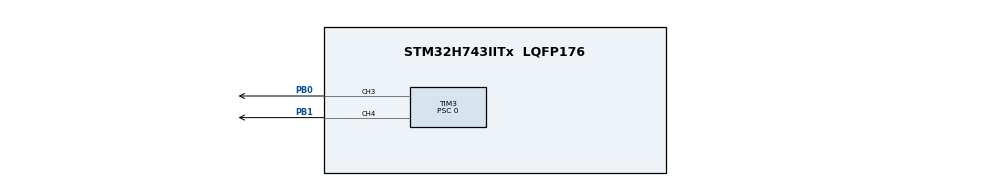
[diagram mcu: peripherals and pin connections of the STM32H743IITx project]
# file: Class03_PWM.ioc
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Mcu.Family=STM32H7
Mcu.Name=STM32H743IITx
Mcu.Package=LQFP176
NVIC.PriorityGroup=NVIC_PRIORITYGROUP_4
PB0.GPIO_Speed=GPIO_SPEED_FREQ_VERY_HIGH
PB0.Signal=S_TIM3_CH3
PB1.GPIO_PuPd=GPIO_NOPULL
PB1.GPIO_Speed=GPIO_SPEED_FREQ_VERY_HIGH
PB1.Signal=S_TIM3_CH4
PH0-OSC_IN.Mode=HSE-External-Oscillator
PH0-OSC_IN.Signal=RCC_OSC_IN
PH1-OSC_OUT.Mode=HSE-External-Oscillator
PH1-OSC_OUT.Signal=RCC_OSC_OUT
ProjectManager.HeapSize=0x200
ProjectManager.StackSize=0x400
ProjectManager.TargetToolchain=MDK-ARM V5
RCC.ADCFreq_Value=50390625
RCC.APB1Freq_Value=100000000
RCC.APB2Freq_Value=100000000
RCC.APB3Freq_Value=100000000
RCC.APB4Freq_Value=100000000
RCC.CortexFreq_Value=400000000
RCC.D1PPRE=RCC_APB3_DIV2
RCC.D2PPRE1=RCC_APB1_DIV2
RCC.D2PPRE2=RCC_APB2_DIV2
RCC.D3PPRE=RCC_APB4_DIV2
RCC.DIVM1=2
RCC.DIVN1=64
RCC.HCLKFreq_Value=200000000
RCC.HPRE=RCC_HCLK_DIV2
RCC.PLLSourceVirtual=RCC_PLLSOURCE_HSE
RCC.SYSCLKFreq_VALUE=400000000
RCC.SYSCLKSource=RCC_SYSCLKSOURCE_PLLCLK
RCC.USBFreq_Value=400000000
SH.S_TIM3_CH3.0=TIM3_CH3,PWM Generation3 CH3
SH.S_TIM3_CH4.0=TIM3_CH4,PWM Generation4 CH4
TIM3.AutoReloadPreload=TIM_AUTORELOAD_PRELOAD_ENABLE
TIM3.Channel-PWM\ Generation3\ CH3=TIM_CHANNEL_3
TIM3.Channel-PWM\ Generation4\ CH4=TIM_CHANNEL_4
TIM3.OCPolarity_3=TIM_OCPOLARITY_LOW
TIM3.OCPolarity_4=TIM_OCPOLARITY_LOW
TIM3.Period=65535
TIM3.Prescaler=0
TIM3.Pulse-PWM\ Generation3\ CH3=32768
TIM3.Pulse-PWM\ Generation4\ CH4=32768
TIM3.TIM_MasterOutputTrigger=TIM_TRGO_RESET
VP_TIM3_VS_ClockSourceINT.Mode=Internal
board=custom

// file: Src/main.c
/**
  ******************************************************************************
  * @file           : main.c
  * @brief          : Main program body
  ******************************************************************************
  ** This notice applies to any and all portions of this file
  * that are not between comment pairs USER CODE BEGIN and
  * USER CODE END. Other portions of this file, whether
  * inserted by the user or by software development tools
  * are owned by their respective copyright owners.
  *
  * COPYRIGHT(c) 2018 STMicroelectronics
  *
  * Redistribution and use in source and binary forms, with or without modification,
  * are permitted provided that the following conditions are met:
  *   1. Redistributions of source code must retain the above copyright notice,
  *      this list of conditions and the following disclaimer.
  *   2. Redistributions in binary form must reproduce the above copyright notice,
  *      this list of conditions and the following disclaimer in the documentation
  *      and/or other materials provided with the distribution.
  *   3. Neither the name of STMicroelectronics nor the names of its contributors
  *      may be used to endorse or promote products derived from this software
  *      without specific prior written permission.
  *
  * THIS SOFTWARE IS PROVIDED BY THE COPYRIGHT HOLDERS AND CONTRIBUTORS "AS IS"
  * AND ANY EXPRESS OR IMPLIED WARRANTIES, INCLUDING, BUT NOT LIMITED TO, THE
  * IMPLIED WARRANTIES OF MERCHANTABILITY AND FITNESS FOR A PARTICULAR PURPOSE ARE
  * DISCLAIMED. IN NO EVENT SHALL THE COPYRIGHT HOLDER OR CONTRIBUTORS BE LIABLE
  * FOR ANY DIRECT, INDIRECT, INCIDENTAL, SPECIAL, EXEMPLARY, OR CONSEQUENTIAL
  * DAMAGES (INCLUDING, BUT NOT LIMITED TO, PROCUREMENT OF SUBSTITUTE GOODS OR
  * SERVICES; LOSS OF USE, DATA, OR PROFITS; OR BUSINESS INTERRUPTION) HOWEVER
  * CAUSED AND ON ANY THEORY OF LIABILITY, WHETHER IN CONTRACT, STRICT LIABILITY,
  * OR TORT (INCLUDING NEGLIGENCE OR OTHERWISE) ARISING IN ANY WAY OUT OF THE USE
  * OF THIS SOFTWARE, EVEN IF ADVISED OF THE POSSIBILITY OF SUCH DAMAGE.
  *
  ******************************************************************************
  */
#include "main.h"
#include "stm32h7xx_hal.h"

TIM_HandleTypeDef htim3;

/* USER CODE BEGIN PV */
/* Private variables ---------------------------------------------------------*/

/* USER CODE END PV */

void SystemClock_Config(void);
static void MX_GPIO_Init(void);
static void MX_TIM3_Init(void);

void HAL_TIM_MspPostInit(TIM_HandleTypeDef *htim);

/* USER CODE BEGIN PFP */
/* Private function prototypes -----------------------------------------------*/

/* USER CODE END PFP */

int main(void)
{
  /* USER CODE BEGIN 1 */
	unsigned int i =0,j=65535,k=65535;
	char flagi = 0,flagj = 0;
  /* USER CODE END 1 */

  /* MCU Configuration----------------------------------------------------------*/

  /* Reset of all peripherals, Initializes the Flash interface and the Systick. */
  HAL_Init();

  /* Configure the system clock */
  SystemClock_Config();

  /* Initialize all configured peripherals */
  MX_GPIO_Init();
  MX_TIM3_Init();
  /* USER CODE BEGIN 2 */
	HAL_TIM_PWM_Start_IT(&htim3,TIM_CHANNEL_4);
	HAL_TIM_PWM_Start_IT(&htim3,TIM_CHANNEL_3);
  /* USER CODE END 2 */

  /* Infinite loop */
  while (1)
  {

  /* USER CODE BEGIN 3 */
		if(i == 0)flagi = 1;
		if(j == 0)flagj = 1;
		if(i == 65535)flagi = 0;
		if(j == 65535)flagj = 0;
		if(flagi)htim3.Instance->CCR3=i++;
		else htim3.Instance->CCR3=i--;
		if(flagj)htim3.Instance->CCR4=j++;
		else htim3.Instance->CCR4=j--;

		k=655;
		while(k--);
		//HAL_Delay(1);
  }
  /* USER CODE END 3 */

}

void SystemClock_Config(void)
{

  RCC_OscInitTypeDef RCC_OscInitStruct;
  RCC_ClkInitTypeDef RCC_ClkInitStruct;

    /**Supply configuration update enable
    */
  MODIFY_REG(PWR->CR3, PWR_CR3_SCUEN, 0);

    /**Configure the main internal regulator output voltage
    */
  __HAL_PWR_VOLTAGESCALING_CONFIG(PWR_REGULATOR_VOLTAGE_SCALE1);

  while ((PWR->D3CR & (PWR_D3CR_VOSRDY)) != PWR_D3CR_VOSRDY)
  {

  }
    /**Initializes the CPU, AHB and APB busses clocks
    */
  RCC_OscInitStruct.OscillatorType = RCC_OSCILLATORTYPE_HSE;
  RCC_OscInitStruct.HSEState = RCC_HSE_ON;
  RCC_OscInitStruct.PLL.PLLState = RCC_PLL_ON;
  RCC_OscInitStruct.PLL.PLLSource = RCC_PLLSOURCE_HSE;
  RCC_OscInitStruct.PLL.PLLM = 2;
  RCC_OscInitStruct.PLL.PLLN = 64;
  RCC_OscInitStruct.PLL.PLLP = 2;
  RCC_OscInitStruct.PLL.PLLQ = 2;
  RCC_OscInitStruct.PLL.PLLR = 2;
  RCC_OscInitStruct.PLL.PLLRGE = RCC_PLL1VCIRANGE_3;
  RCC_OscInitStruct.PLL.PLLVCOSEL = RCC_PLL1VCOWIDE;
  RCC_OscInitStruct.PLL.PLLFRACN = 0;
  if (HAL_RCC_OscConfig(&RCC_OscInitStruct) != HAL_OK)
  {
    _Error_Handler(__FILE__, __LINE__);
  }

    /**Initializes the CPU, AHB and APB busses clocks
    */
  RCC_ClkInitStruct.ClockType = RCC_CLOCKTYPE_HCLK|RCC_CLOCKTYPE_SYSCLK
                              |RCC_CLOCKTYPE_PCLK1|RCC_CLOCKTYPE_PCLK2
                              |RCC_CLOCKTYPE_D3PCLK1|RCC_CLOCKTYPE_D1PCLK1;
  RCC_ClkInitStruct.SYSCLKSource = RCC_SYSCLKSOURCE_PLLCLK;
  RCC_ClkInitStruct.SYSCLKDivider = RCC_SYSCLK_DIV1;
  RCC_ClkInitStruct.AHBCLKDivider = RCC_HCLK_DIV2;
  RCC_ClkInitStruct.APB3CLKDivider = RCC_APB3_DIV2;
  RCC_ClkInitStruct.APB1CLKDivider = RCC_APB1_DIV2;
  RCC_ClkInitStruct.APB2CLKDivider = RCC_APB2_DIV2;
  RCC_ClkInitStruct.APB4CLKDivider = RCC_APB4_DIV2;

  if (HAL_RCC_ClockConfig(&RCC_ClkInitStruct, FLASH_LATENCY_2) != HAL_OK)
  {
    _Error_Handler(__FILE__, __LINE__);
  }

    /**Configure the Systick interrupt time
    */
  HAL_SYSTICK_Config(SystemCoreClock/1000);

    /**Configure the Systick
    */
  HAL_SYSTICK_CLKSourceConfig(SYSTICK_CLKSOURCE_HCLK);

  /* SysTick_IRQn interrupt configuration */
  HAL_NVIC_SetPriority(SysTick_IRQn, 0, 0);
}

/* TIM3 init function */
static void MX_TIM3_Init(void)
{

  TIM_ClockConfigTypeDef sClockSourceConfig;
  TIM_MasterConfigTypeDef sMasterConfig;
  TIM_OC_InitTypeDef sConfigOC;

  htim3.Instance = TIM3;
  htim3.Init.Prescaler = 0;
  htim3.Init.CounterMode = TIM_COUNTERMODE_UP;
  htim3.Init.Period = 65535;
  htim3.Init.ClockDivision = TIM_CLOCKDIVISION_DIV1;
  htim3.Init.AutoReloadPreload = TIM_AUTORELOAD_PRELOAD_ENABLE;
  if (HAL_TIM_Base_Init(&htim3) != HAL_OK)
  {
    _Error_Handler(__FILE__, __LINE__);
  }

  sClockSourceConfig.ClockSource = TIM_CLOCKSOURCE_INTERNAL;
  if (HAL_TIM_ConfigClockSource(&htim3, &sClockSourceConfig) != HAL_OK)
  {
    _Error_Handler(__FILE__, __LINE__);
  }

  if (HAL_TIM_PWM_Init(&htim3) != HAL_OK)
  {
    _Error_Handler(__FILE__, __LINE__);
  }

  sMasterConfig.MasterOutputTrigger = TIM_TRGO_RESET;
  sMasterConfig.MasterSlaveMode = TIM_MASTERSLAVEMODE_DISABLE;
  if (HAL_TIMEx_MasterConfigSynchronization(&htim3, &sMasterConfig) != HAL_OK)
  {
    _Error_Handler(__FILE__, __LINE__);
  }

  sConfigOC.OCMode = TIM_OCMODE_PWM1;
  sConfigOC.Pulse = 32768;
  sConfigOC.OCPolarity = TIM_OCPOLARITY_LOW;
  sConfigOC.OCFastMode = TIM_OCFAST_DISABLE;
  if (HAL_TIM_PWM_ConfigChannel(&htim3, &sConfigOC, TIM_CHANNEL_3) != HAL_OK)
  {
    _Error_Handler(__FILE__, __LINE__);
  }

  if (HAL_TIM_PWM_ConfigChannel(&htim3, &sConfigOC, TIM_CHANNEL_4) != HAL_OK)
  {
    _Error_Handler(__FILE__, __LINE__);
  }

  HAL_TIM_MspPostInit(&htim3);

}

/** Configure pins as
        * Analog
        * Input
        * Output
        * EVENT_OUT
        * EXTI
*/
static void MX_GPIO_Init(void)
{

  /* GPIO Ports Clock Enable */
  __HAL_RCC_GPIOH_CLK_ENABLE();
  __HAL_RCC_GPIOB_CLK_ENABLE();

}

void _Error_Handler(char *file, int line)
{
  while(1)
  {
  }
}

/************************ (C) COPYRIGHT STMicroelectronics *****END OF FILE****/
